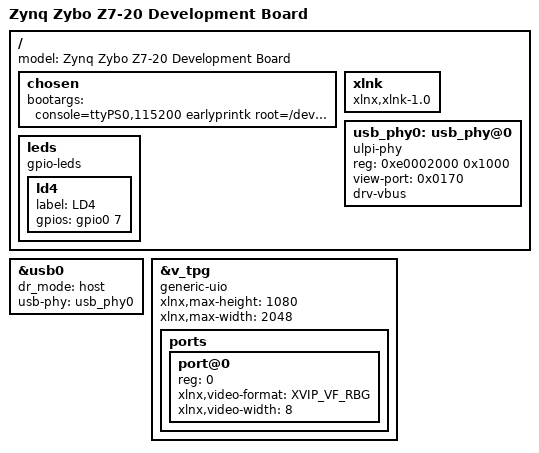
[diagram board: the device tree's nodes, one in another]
#include <dt-bindings/gpio/gpio.h>
#include <dt-bindings/media/xilinx-vip.h>

/include/ "system-conf.dtsi"
/ {
	model = "Zynq Zybo Z7-20 Development Board";

	chosen {
		bootargs = "console=ttyPS0,115200 earlyprintk root=/dev/mmcblk0p2 rw rootwait rootfstype=ext4 uio_pdrv_genirq.of_id=generic-uio";
	};

	xlnk {
		compatible = "xlnx,xlnk-1.0";
	};

	usb_phy0: usb_phy@0 {
		compatible = "ulpi-phy";
		#phy-cells = <0>;
		reg = <0xe0002000 0x1000>;
		view-port = <0x0170>;
		drv-vbus;
	};

	leds {
		compatible = "gpio-leds";
		ld4 {
			label = "LD4";
			gpios = <&gpio0 7 GPIO_ACTIVE_HIGH>;
		};
	};
};

&usb0 {	
	dr_mode = "host";
	usb-phy = <&usb_phy0>;
};

&v_tpg {
	compatible = "generic-uio";

	xlnx,max-height = <1080>;
	xlnx,max-width = <2048>;
//	xlnx,ppc = <1>;

	ports {
		#address-cells = <1>;
		#size-cells = <0>;
		port@0 {
				reg = <0>;
				xlnx,video-format = <XVIP_VF_RBG>;
				xlnx,video-width = <8>;
		};
	};
};
